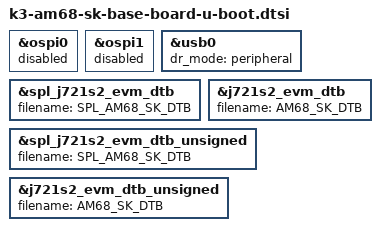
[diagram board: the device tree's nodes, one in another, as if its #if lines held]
// SPDX-License-Identifier: GPL-2.0
/*
 * Copyright (C) 2022-2023 Texas Instruments Incorporated - https://www.ti.com/
 */

#include "k3-j721s2-binman.dtsi"

&ospi0 {
	status = "disabled";
};

&ospi1 {
	status = "disabled";
};

&usb0 {
	dr_mode = "peripheral";
};

#ifdef CONFIG_TARGET_J721S2_A72_EVM

#define SPL_AM68_SK_DTB "spl/dts/ti/k3-am68-sk-base-board.dtb"
#define AM68_SK_DTB "u-boot.dtb"

&spl_j721s2_evm_dtb {
	filename = SPL_AM68_SK_DTB;
};

&j721s2_evm_dtb {
	filename = AM68_SK_DTB;
};

&spl_j721s2_evm_dtb_unsigned {
	filename = SPL_AM68_SK_DTB;
};

&j721s2_evm_dtb_unsigned {
	filename = AM68_SK_DTB;
};

#endif
